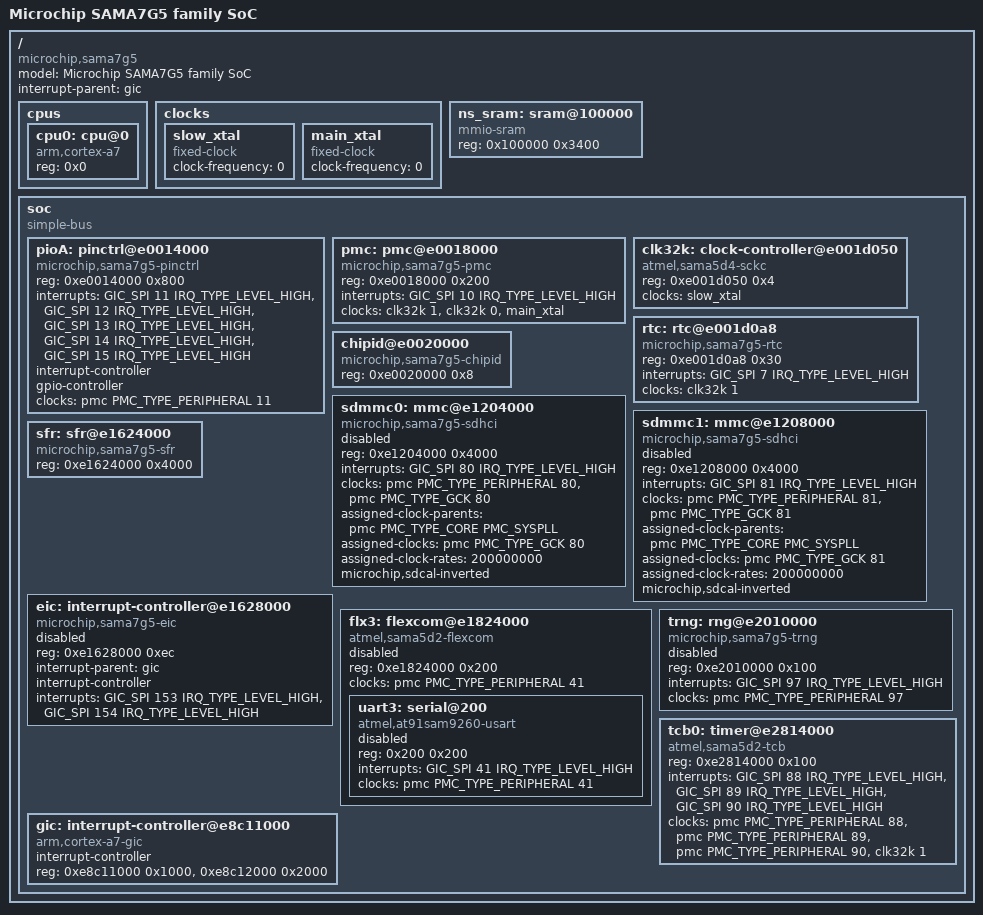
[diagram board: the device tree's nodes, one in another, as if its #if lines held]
// SPDX-License-Identifier: (GPL-2.0+ OR MIT)
/*
 *  sama7g5.dtsi - Device Tree Include file for SAMA7G5 family SoC
 *
 *  Copyright (C) 2020 Microchip Technology, Inc. and its subsidiaries
 *
 *  Author: Eugen Hristev <eugen.hristev@microchip.com>
 *  Author: Claudiu Beznea <claudiu.beznea@microchip.com>
 *
 */

#include <dt-bindings/iio/adc/at91-sama5d2_adc.h>
#include <dt-bindings/interrupt-controller/irq.h>
#include <dt-bindings/interrupt-controller/arm-gic.h>
#include <dt-bindings/reset/sama7g5-reset.h>
#include <dt-bindings/clock/at91.h>
#include <dt-bindings/dma/at91.h>
#include <dt-bindings/gpio/gpio.h>
#include <dt-bindings/nvmem/microchip,otpc.h>
#include <dt-bindings/thermal/thermal.h>

/ {
	model = "Microchip SAMA7G5 family SoC";
	compatible = "microchip,sama7g5";
	#address-cells = <1>;
	#size-cells = <1>;
	interrupt-parent = <&gic>;

	cpus {
		#address-cells = <1>;
		#size-cells = <0>;

		cpu0: cpu@0 {
			device_type = "cpu";
			compatible = "arm,cortex-a7";
			reg = <0x0>;
		};
	};

	clocks {
		slow_xtal: slow_xtal {
			compatible = "fixed-clock";
			#clock-cells = <0>;
			clock-frequency = <0>;
		};

		main_xtal: main_xtal {
			compatible = "fixed-clock";
			#clock-cells = <0>;
			clock-frequency = <0>;
		};
	};

	ns_sram: sram@100000 {
		compatible = "mmio-sram";
		#address-cells = <1>;
		#size-cells = <1>;
		reg = <0x100000 0x3400>;
		ranges;
	};

	soc {
		compatible = "simple-bus";
		#address-cells = <1>;
		#size-cells = <1>;
		ranges;

		pioA: pinctrl@e0014000 {
			compatible = "microchip,sama7g5-pinctrl";
			reg = <0xe0014000 0x800>;
			interrupts = <GIC_SPI 11 IRQ_TYPE_LEVEL_HIGH>,
				<GIC_SPI 12 IRQ_TYPE_LEVEL_HIGH>,
				<GIC_SPI 13 IRQ_TYPE_LEVEL_HIGH>,
				<GIC_SPI 14 IRQ_TYPE_LEVEL_HIGH>,
				<GIC_SPI 15 IRQ_TYPE_LEVEL_HIGH>;
			interrupt-controller;
			#interrupt-cells = <2>;
			gpio-controller;
			#gpio-cells = <2>;
			clocks = <&pmc PMC_TYPE_PERIPHERAL 11>;
		};

		pmc: pmc@e0018000 {
			compatible = "microchip,sama7g5-pmc", "syscon";
			reg = <0xe0018000 0x200>;
			interrupts = <GIC_SPI 10 IRQ_TYPE_LEVEL_HIGH>;
			#clock-cells = <2>;
			clocks = <&clk32k 1>, <&clk32k 0>, <&main_xtal>;
#ifdef CONFIG_OPTEE
			clock-names = "slow_clk", "md_slck", "main_xtal";
#else
			clock-names = "td_slck", "md_slck", "main_xtal";
#endif
		};

		clk32k: clock-controller@e001d050 {
#ifdef CONFIG_OPTEE
			compatible = "atmel,sama5d4-sckc";
#else
			compatible = "microchip,sama7g5-sckc", "microchip,sam9x60-sckc";
#endif
			reg = <0xe001d050 0x4>;
			clocks = <&slow_xtal>;
			#clock-cells = <1>;
		};

		rtc: rtc@e001d0a8 {
			compatible = "microchip,sama7g5-rtc", "microchip,sam9x60-rtc";
			reg = <0xe001d0a8 0x30>;
			interrupts = <GIC_SPI 7 IRQ_TYPE_LEVEL_HIGH>;
			clocks = <&clk32k 1>;
		};

		chipid@e0020000 {
			compatible = "microchip,sama7g5-chipid";
			reg = <0xe0020000 0x8>;
		};

		sdmmc0: mmc@e1204000 {
			compatible = "microchip,sama7g5-sdhci", "microchip,sam9x60-sdhci";
			reg = <0xe1204000 0x4000>;
			interrupts = <GIC_SPI 80 IRQ_TYPE_LEVEL_HIGH>;
			clocks = <&pmc PMC_TYPE_PERIPHERAL 80>, <&pmc PMC_TYPE_GCK 80>;
			clock-names = "hclock", "multclk";
			assigned-clock-parents = <&pmc PMC_TYPE_CORE PMC_SYSPLL>;
			assigned-clocks = <&pmc PMC_TYPE_GCK 80>;
			assigned-clock-rates = <200000000>;
			microchip,sdcal-inverted;
			status = "disabled";
		};

		sdmmc1: mmc@e1208000 {
			compatible = "microchip,sama7g5-sdhci", "microchip,sam9x60-sdhci";
			reg = <0xe1208000 0x4000>;
			interrupts = <GIC_SPI 81 IRQ_TYPE_LEVEL_HIGH>;
			clocks = <&pmc PMC_TYPE_PERIPHERAL 81>, <&pmc PMC_TYPE_GCK 81>;
			clock-names = "hclock", "multclk";
			assigned-clock-parents = <&pmc PMC_TYPE_CORE PMC_SYSPLL>;
			assigned-clocks = <&pmc PMC_TYPE_GCK 81>;
			assigned-clock-rates = <200000000>;
			microchip,sdcal-inverted;
			status = "disabled";
		};

		sfr: sfr@e1624000 {
			compatible = "microchip,sama7g5-sfr", "syscon";
			reg = <0xe1624000 0x4000>;
		};

		eic: interrupt-controller@e1628000 {
			compatible = "microchip,sama7g5-eic";
			reg = <0xe1628000 0xec>;
			interrupt-parent = <&gic>;
			interrupt-controller;
			#interrupt-cells = <2>;
			interrupts = <GIC_SPI 153 IRQ_TYPE_LEVEL_HIGH>,
				     <GIC_SPI 154 IRQ_TYPE_LEVEL_HIGH>;
#ifdef CONFIG_OPTEE
#else
			clocks = <&pmc PMC_TYPE_PERIPHERAL 37>;
			clock-names = "pclk";
#endif
			status = "disabled";
		};

		flx3: flexcom@e1824000 {
			compatible = "atmel,sama5d2-flexcom";
			reg = <0xe1824000 0x200>;
			clocks = <&pmc PMC_TYPE_PERIPHERAL 41>;
			#address-cells = <1>;
			#size-cells = <1>;
			ranges = <0x0 0xe1824000 0x800>;
			status = "disabled";

			uart3: serial@200 {
				compatible = "atmel,at91sam9260-usart";
				reg = <0x200 0x200>;
				interrupts = <GIC_SPI 41 IRQ_TYPE_LEVEL_HIGH>;
				clocks = <&pmc PMC_TYPE_PERIPHERAL 41>;
				clock-names = "usart";
				status = "disabled";
			};
		};

		trng: rng@e2010000 {
			compatible = "microchip,sama7g5-trng", "atmel,at91sam9g45-trng";
			reg = <0xe2010000 0x100>;
			interrupts = <GIC_SPI 97 IRQ_TYPE_LEVEL_HIGH>;
			clocks = <&pmc PMC_TYPE_PERIPHERAL 97>;
			status = "disabled";
		};

		tcb0: timer@e2814000 {
			compatible = "atmel,sama5d2-tcb", "simple-mfd", "syscon";
			#address-cells = <1>;
			#size-cells = <0>;
			reg = <0xe2814000 0x100>;
			interrupts = <GIC_SPI 88 IRQ_TYPE_LEVEL_HIGH>, <GIC_SPI 89 IRQ_TYPE_LEVEL_HIGH>, <GIC_SPI 90 IRQ_TYPE_LEVEL_HIGH>;
			clocks = <&pmc PMC_TYPE_PERIPHERAL 88>, <&pmc PMC_TYPE_PERIPHERAL 89>, <&pmc PMC_TYPE_PERIPHERAL 90>, <&clk32k 1>;
			clock-names = "t0_clk", "t1_clk", "t2_clk", "slow_clk";
		};

		gic: interrupt-controller@e8c11000 {
			compatible = "arm,cortex-a7-gic";
			#interrupt-cells = <3>;
			#address-cells = <0>;
			interrupt-controller;
			reg = <0xe8c11000 0x1000>,
				<0xe8c12000 0x2000>;
		};
	};
};
